# SSE300 register map
Vendor: ARM Ltd.; Series: ARMv8.1-M Mainline; File version: 1.0
CPU: CM55 r0p0, little endian, MPU, FPU, 3 interrupt priority bits, 8 SAU regions
Registers are 32-bit, read-write, reset 0x0 unless marked. A register's access mark holds for its fields unless they carry their own. Offsets are from the block's base; [hi:lo] are bit positions; {n}, {i} and the like mark numbered series; 'fields as' and 'values as' point back to an identical list.

## SACRB — Secure Access Configuration Register Block
Base 0x50080000
0x00 SPCSECTRL — Secure Privilege Controller Secure Configuration Control register
0x04 BUSWAIT — Bus Access wait control after reset
0x10 SECRESPCFG — Security Violation Response Configuration register
0x14 NSCCFG — Non Secure Callable Configuration for IDAU
0x1C SECMPCINTSTATUS ro — Secure MPC Interrupt Status
0x20 SECPPCINTSTAT ro — Secure PPC Interrupt Status
0x24 SECPPCINTCLR wo — Secure PPC Interrupt Clear
0x28 SECPPCINTEN — Secure PPC Interrupt Enable
0x30 SECMSCINTSTAT ro — Secure MSC Interrupt Status
0x34 SECMSCINTCLR — Secure MSC Interrupt Clear
0x38 SECMSCINTEN — Secure MSC Interrupt Enable
0x40 BRGINTSTAT ro — Bridge Buffer Error Interrupt Status
0x44 BRGINTCLR wo — Bridge Buffer Error Interrupt Clear
0x48 BRGINTEN — Bridge Buffer Error Interrupt Enable
0x50 AHBNSPPC0 — Non-Secure Access AHB slave Peripheral Protection Control 0
{0x60+4i} AHBNSPPCEXP{i} (i=0..3) — Expansion {i} Non_Secure Access AHB slave Peripheral Protection Control
0x70 APBNSPPC0 — Non-Secure Access APB slave Peripheral Protection Control 0
0x74 APBNSPPC1 — Non-Secure Access APB slave Peripheral Protection Control 1
{0x80+4i} APBNSPPCEXP{i} (i=0..3) — Expansion {i} Non_Secure Access APB slave Peripheral Protection Control
0x90 AHBSPPPC0 ro — Secure Unprivileged Access AHB slave Peripheral Protection Control 0
{0xA0+4i} AHBSPPPCEXP{i} (i=0..3) — Expansion {i} Secure Unprivileged Access AHB slave Peripheral Protection Control
0xB0 APBSPPPC0 — Secure Unprivileged Access APB slave Peripheral Protection Control 0
0xB4 APBSPPPC1 — Secure Unprivileged Access APB slave Peripheral Protection Control 1
{0xC0+4i} APBSPPPCEXP{i} (i=0..3) — Expansion {i} Secure Unprivileged Access APB slave Peripheral Protection Control
0xD0 NSMSCEXP ro — Expansion MSC Non-Secure Configuration
0xFD0 PID4 ro reset 0x4 — Peripheral ID 4
0xFE0 PID0 ro reset 0x52 — Peripheral ID 0
0xFE4 PID1 ro reset 0xB8 — Peripheral ID 1
0xFE8 PID2 ro reset 0xB — Peripheral ID 2
0xFEC PID3 ro — Peripheral ID 3
0xFF0 CIDR0 ro reset 0xD — Component ID 0
0xFF4 CIDR1 ro reset 0xF0 — Component ID 1
0xFF8 CIDR2 ro reset 0x5 — Component ID 2
0xFFC CIDR3 ro reset 0xB1 — Component ID 3

## NSACRB — Non-secure Access Configuration Register Block
Base 0x40080000
0x90 AHBNSPPPC0 — Non-Secure Unprivileged Access AHB slave Peripheral Protection Control #0
{0xA0+4i} AHBNSPPPCEXP{i} (i=0..3) — Expansion {i} Non_Secure Unprivileged Access AHB slave Peripheral Protection Control
0xB0 APBNSPPPC0 — Non-Secure Unprivileged Access APB slave Peripheral Protection Control 0
0xB4 APBNSPPPC1 — Non-Secure Unprivileged Access APB slave Peripheral Protection Control 1
{0xC0+4i} APBNSPPPCEXP{i} (i=0..3) — Expansion {i} Non_Secure Unprivileged Access APB slave Peripheral Protection Control
0xFD0 PIDR4 ro — Peripheral ID 4
0xFE0 PIDR0 ro reset 0x53 — Peripheral ID 0
0xFE4 PIDR1 ro reset 0xB8 — Peripheral ID 1
0xFE8 PIDR2 ro reset 0xB — Peripheral ID 2
0xFEC PIDR3 ro — Peripheral ID 3
0xFF0 CIDR0 ro reset 0xD — Component ID 0
0xFF4 CIDR1 ro reset 0xF0 — Component ID 1
0xFF8 CIDR2 ro reset 0x5 — Component ID 2
0xFFC CIDR3 ro reset 0xB1 — Component ID 3

## ISRAM0MPC — ISRAM 0 Memory Protection Controller
Base 0x50083000
Same registers: ISRAM1MPC 0x50084000
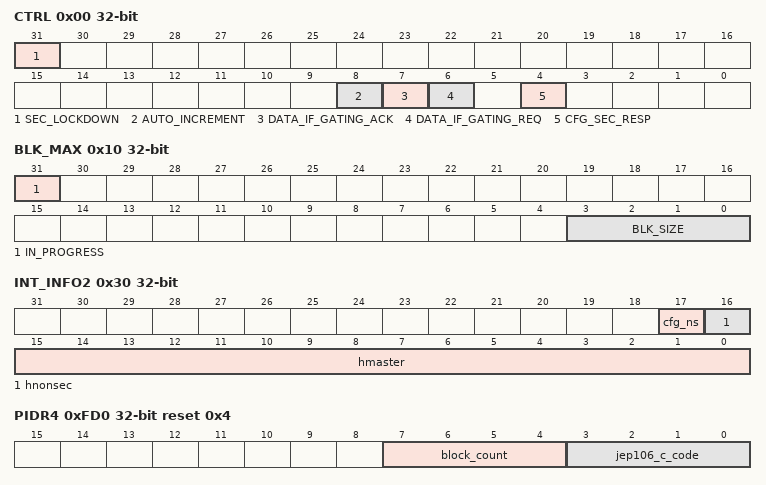
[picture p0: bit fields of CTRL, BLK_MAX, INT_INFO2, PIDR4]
0x00 CTRL — MPC Control register
  [31] SEC_LOCKDOWN — Security lockdown
  [8] AUTO_INCREMENT
  [7] DATA_IF_GATING_ACK ro — Data interface gating acknowledge (RO)
  [6] DATA_IF_GATING_REQ — Data interface gating request
  [4] CFG_SEC_RESP — Security error response configuration
    0=RAZ_WI (Read-As-Zero - Writes ignored); 1=BUSERROR
0x10 BLK_MAX ro — Maximum value of block based index register
  [31] IN_PROGRESS — Initialization in progress
  [3:0] BLK_SIZE — Block size
0x14 BLK_CFG ro — Block Configuration
0x18 BLK_IDX — Index value for accessing block based look up table
0x1C BLK_LUT — Block based gating Look Up Table
0x20 INT_STAT ro — Interrupt state
  [0] mpc_irq — mpc_irq triggered
0x24 INT_CLEAR wo — Interrupt clear
  [0] mpc_irq — mpc_irq clear (cleared automatically)
0x28 INT_EN — Interrupt enable
  [0] mpc_irq — mpc_irq enable. Bits are valid when mpc_irq triggered is set
0x2C INT_INFO1 ro — Interrupt information 1
0x30 INT_INFO2 ro — Interrupt information 2
  [17] cfg_ns, [16] hnonsec, [15:0] hmaster
0x34 INT_SET wo — Interrupt set. Debug purpose only
  [0] mpc_irq — mpc_irq set. Debug purpose only
0xFD0 PIDR4 ro reset 0x4 — Peripheral ID 4
  [7:4] block_count, [3:0] jep106_c_code
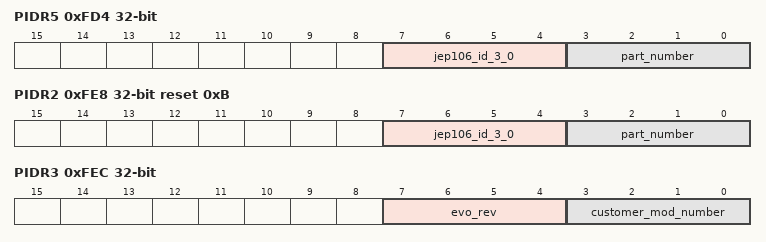
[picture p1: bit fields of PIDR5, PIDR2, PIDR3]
0xFD4 PIDR5 ro — Peripheral ID 5
  [7:4] jep106_id_3_0, [3:0] part_number
0xFD8 PIDR6 ro — Peripheral ID 6
0xFDC PIDR7 ro — Peripheral ID 7
0xFE0 PIDR0 ro reset 0x60 — Peripheral ID 0
0xFE4 PIDR1 ro reset 0xB8 — Peripheral ID 1
0xFE8 PIDR2 ro reset 0xB — Peripheral ID 2
  [7:4] jep106_id_3_0, [3:0] part_number
0xFEC PIDR3 ro — Peripheral ID 3
  [7:4] evo_rev — ECO revision number
  [3:0] customer_mod_number — Customer modification number
0xFF0 CIDR0 ro reset 0xD — Component ID 0
0xFF4 CIDR1 ro reset 0xF0 — Component ID 1
0xFF8 CIDR2 ro reset 0x5 — Component ID 2
0xFFC CIDR3 ro reset 0xB1 — Component ID 3

## AudioI2S
Base 0x49301000
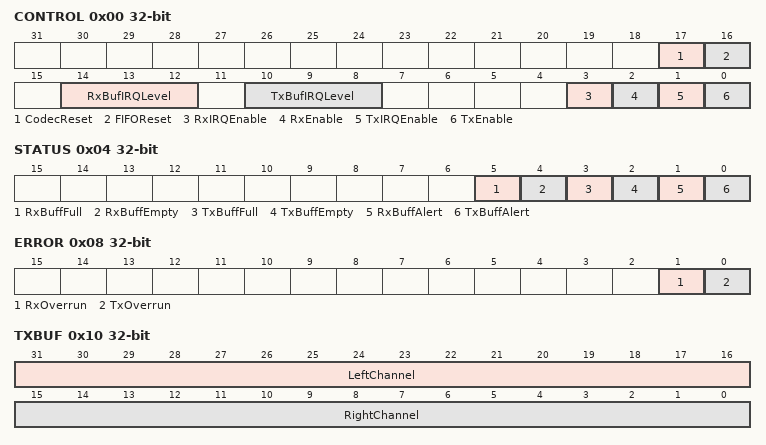
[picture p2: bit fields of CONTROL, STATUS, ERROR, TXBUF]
0x00 CONTROL
  [17] CodecReset — Audio codec reset control
  [16] FIFOReset
  [14:12] RxBufIRQLevel — Receive Buffer IRQ Water level
  [10:8] TxBufIRQLevel — Transmit Buffer IRQ Water level
  [3] RxIRQEnable — Enable Interrupt on Receive Buffer
  [2] RxEnable — Enable Receive Buffer
  [1] TxIRQEnable — Enable Interrupt on Transmit Buffer
  [0] TxEnable — Enable Transfer Buffer
0x04 STATUS ro
  [5] RxBuffFull — Receive Buffer Full
  [4] RxBuffEmpty — Receive Buffer Empty
  [3] TxBuffFull — Transmit Buffer Full
  [2] TxBuffEmpty — Transmit Buffer Empty
  [1] RxBuffAlert — Receive Buffer Alert (Depends on Water level)
  [0] TxBuffAlert — Transmit Buffer Alert (Depends on Water level)
0x08 ERROR — Error status register
  [1] RxOverrun — Receive buffer ovverrun. Set this bit to clear.
  [0] TxOverrun — Transmit buffer ovverrun or underrun. Set this bit to clear.
0x0C DIVIDE — Clock Divide Ratio register
  [9:0] LRDIV — Left/Right. The default value is 0x80
0x10 TXBUF wo — Transmit Buffer FIFO Data register
  [31:16] LeftChannel — Left channel value
  [15:0] RightChannel — Right channel value
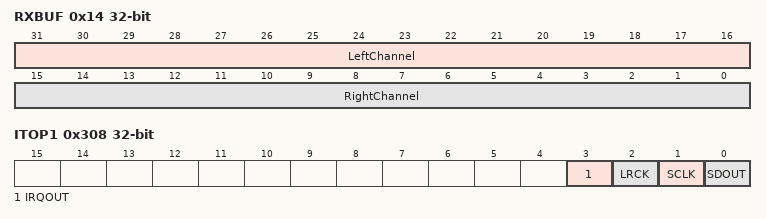
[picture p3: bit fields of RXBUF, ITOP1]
0x14 RXBUF ro — Receive Buffer FIFO Data register
  fields as TXBUF
0x300 ITCR — Integration Test Control register
  [0] ITCR — Integration test control bit
0x304 ITIP1 — Integration Test Input register 1
  [0] SDIN — SDIN pin value
0x308 ITOP1 — Integration Test Output register 1
  [3] IRQOUT — IRQOUT signal value
  [2] LRCK — LRCK signal value
  [1] SCLK — SLCK signal value
  [0] SDOUT — SDOUT signal value

## ColorLCD — Color LCD (Non-Secure)
Base 0x4930A000
Same registers: ColorLCD_Secure 0x5930A000
0x00 CHAR_COM — Command register
0x04 CHAR_DAT — Data register
0x08 CHAR_RD ro — Read Data register
  [7:0] CapturedData — Captured data from an earlier read command. These bits contain the data from the last request read. Valid only when CHAR_RAW[0] is set.
0x0C CHAR_RAW — Access Complete Status register
  [0] AccessCmpltStat — Access complete status. 1 indicates Access Complete and data in CHAR_RD is valid. Write 0 to clear access complete flag.
0x10 CHAR_MASK wo — Interrupt Mask register
  [0] WriteInterruptMask — Write 0 to enable Access Complete to generate an interrupt.
0x14 CHAR_STAT ro — Status register
  [0] AccesCmpltAndIrq — The state of Access Complete ANDed with the CHAR_MASK.
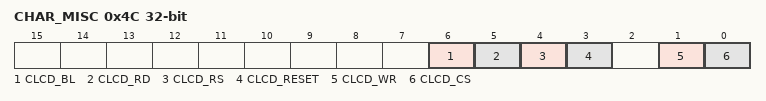
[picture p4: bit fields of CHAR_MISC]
0x4C CHAR_MISC — Miscellaneous Control register
  [6] CLCD_BL, [5] CLCD_RD, [4] CLCD_RS, [3] CLCD_RESET, [1] CLCD_WR, [0] CLCD_CS
